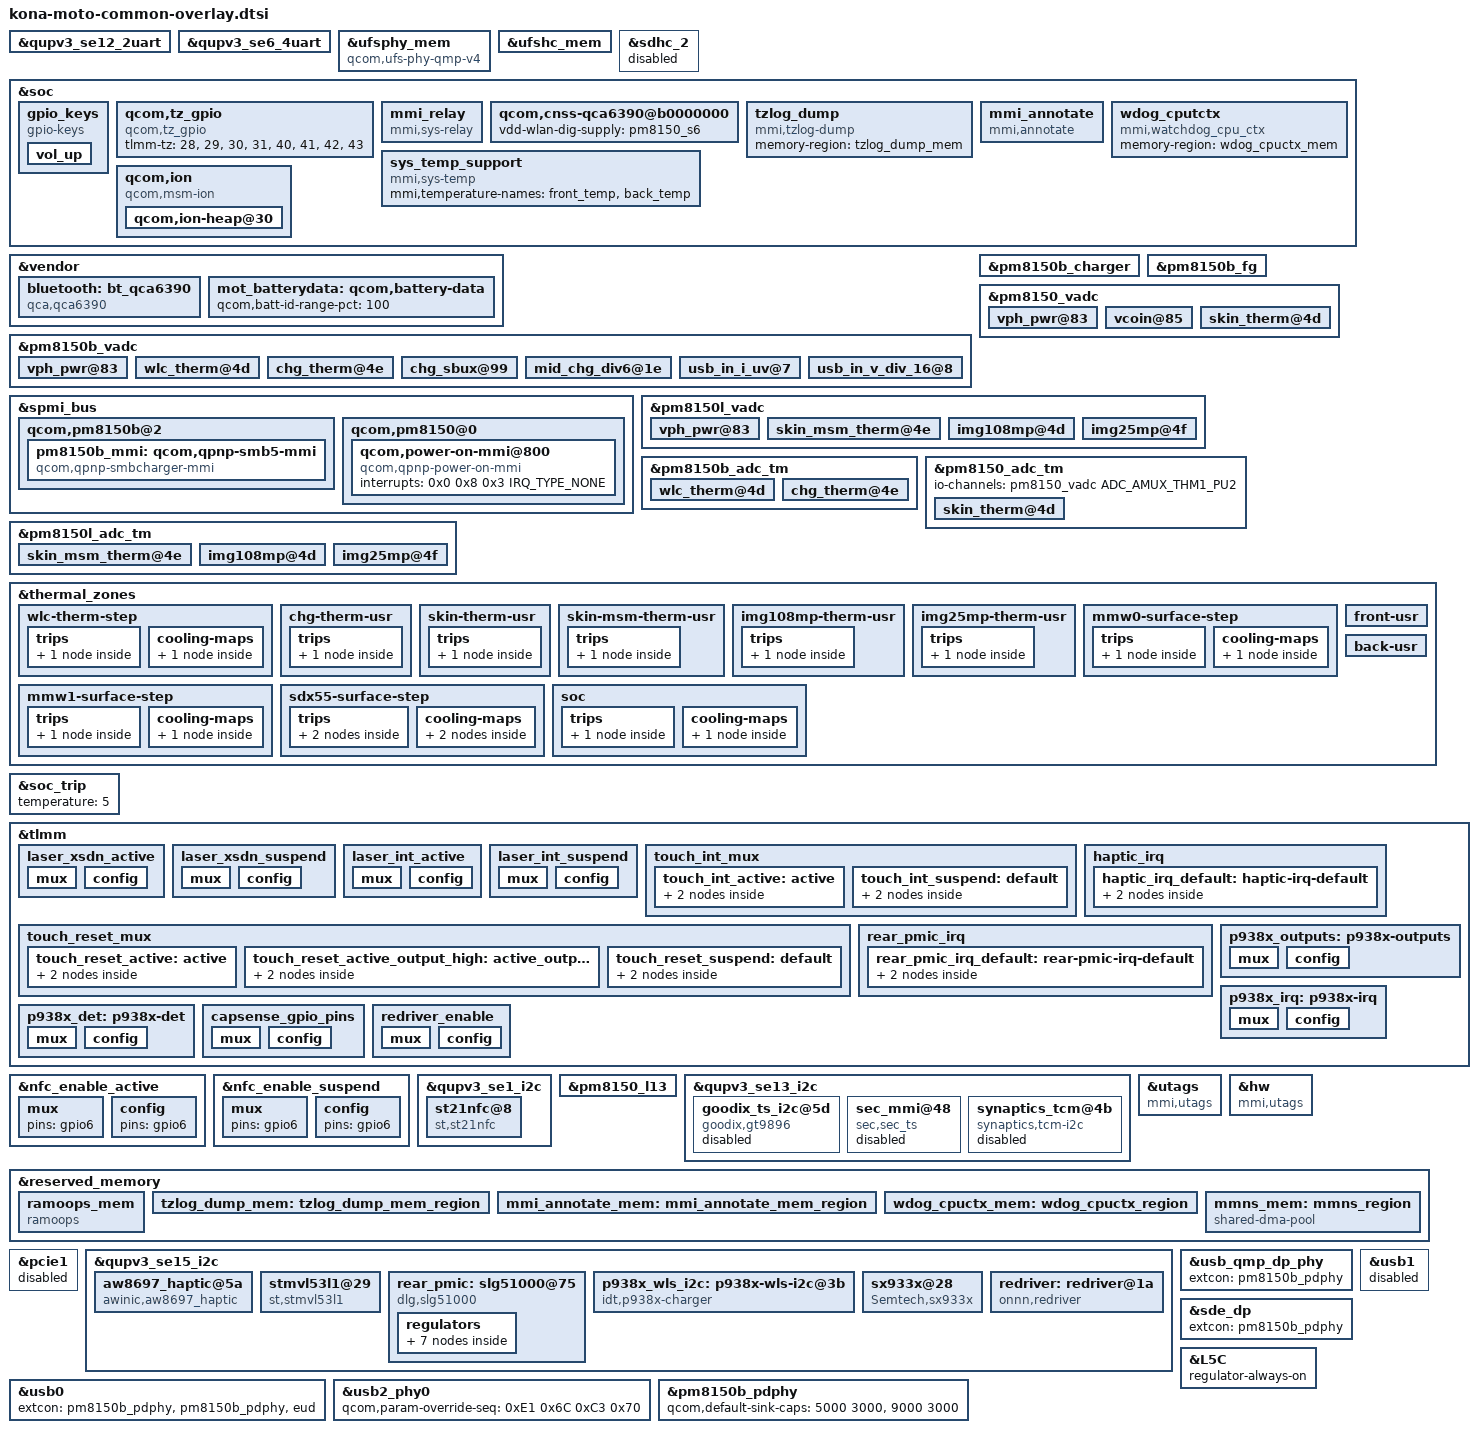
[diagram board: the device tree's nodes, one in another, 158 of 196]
#include <dt-bindings/gpio/gpio.h>
#include <dt-bindings/input/input.h>
#include "carrier-channel-ids.dtsi"

#include "camera/kona-camera-sensor-mot-burton.dtsi"
#include "kona-pmic-overlay.dtsi"
#include "kona-mot-burton-display.dtsi"
#include "kona-thermal-overlay.dtsi"
#include "kona-moto-audio-overlay.dtsi"
#include "kona-mot-burton-fps.dtsi"
&qupv3_se12_2uart {
	status = "ok";
};

&qupv3_se6_4uart {
	status = "ok";
};

&ufsphy_mem {
	compatible = "qcom,ufs-phy-qmp-v4";

	vdda-phy-supply = <&pm8150_l5>;
	vdda-phy-always-on;
	vdda-pll-supply = <&pm8150_l9>;
	vdda-phy-max-microamp = <89900>;
	vdda-pll-max-microamp = <18800>;

	status = "ok";
};

&ufshc_mem {
	vdd-hba-supply = <&ufs_phy_gdsc>;
	vdd-hba-fixed-regulator;
	vcc-supply = <&pm8150_l17>;
	vcc-voltage-level = <2504000 2950000>;
	vcc-low-voltage-sup;
	vccq-supply = <&pm8150_l6>;
	vccq2-supply = <&pm8150_s4>;
	vcc-max-microamp = <800000>;
	vccq-max-microamp = <800000>;
	vccq2-max-microamp = <800000>;

	qcom,vddp-ref-clk-supply = <&pm8150_l6>;
	qcom,vddp-ref-clk-max-microamp = <100>;
	qcom,vccq-parent-supply = <&pm8150a_s8>;
	qcom,vccq-parent-max-microamp = <210000>;

	status = "ok";
};

&sdhc_2 {
	status = "disabled";
};

&soc {
	gpio_keys {
		compatible = "gpio-keys";
		label = "gpio-keys";

		pinctrl-names = "default";
		pinctrl-0 = <&key_vol_up_default>;

		vol_up {
			label = "volume_up";
			gpios = <&pm8150_gpios 6 GPIO_ACTIVE_LOW>;
			linux,input-type = <1>;
			linux,code = <KEY_VOLUMEUP>;
			gpio-key,wakeup;
			debounce-interval = <15>;
			linux,can-disable;
		};
	};

	qcom,tz_gpio {
		compatible = "qcom,tz_gpio";
		tlmm-tz = <28>,
			<29>,
			<30>,
			<31>,
			<40>,
			<41>,
			<42>,
			<43>;
	};

	mmi_relay {
		compatible = "mmi,sys-relay";
	};
};

&vendor {
	bluetooth: bt_qca6390 {
		compatible = "qca,qca6390";
		pinctrl-names = "default";
		pinctrl-0 = <&bt_en_sleep>;
		qca,bt-reset-gpio = <&tlmm 21 0>; /* BT_EN */
		qca,bt-vdd-aon-supply = <&pm8150_s6>;
		qca,bt-vdd-dig-supply = <&pm8150_s6>;
		qca,bt-vdd-rfa1-supply = <&pm8150_s5>;
		qca,bt-vdd-rfa2-supply = <&pm8150a_s8>;

		qca,bt-vdd-aon-voltage-level = <950000 950000>;
		qca,bt-vdd-dig-voltage-level = <950000 952000>;
		qca,bt-vdd-rfa1-voltage-level = <1900000 1900000>;
		qca,bt-vdd-rfa2-voltage-level = <1350000 1350000>;

	};

	mot_batterydata: qcom,battery-data {
		qcom,batt-id-range-pct = <100>;
		#include "fg-gen4-batterydata-LW50_5000mAh.dtsi"
	};
};

&soc {
	qcom,cnss-qca6390@b0000000 {
		vdd-wlan-dig-supply = <&pm8150_s6>;
	};
};

&pm8150b_vadc {
	#address-cells = <1>;
	#size-cells = <0>;

	vph_pwr@83 {
		reg = <ADC_VPH_PWR>;
		label = "vph_pwr";
		qcom,pre-scaling = <1 3>;
	};

	wlc_therm@4d {
		reg = <ADC_AMUX_THM1_PU2>;
		label = "wlc_therm";
		qcom,ratiometric;
		qcom,hw-settle-time = <200>;
		qcom,pre-scaling = <1 1>;
	};

	chg_therm@4e {
		reg = <ADC_AMUX_THM2_PU2>;
		label = "chg_therm";
		qcom,ratiometric;
		qcom,hw-settle-time = <200>;
		qcom,pre-scaling = <1 1>;
	};

	chg_sbux@99 {
		reg = <ADC_SBUx>;
		label = "chg_sbux";
		qcom,pre-scaling = <1 3>;
	};

	mid_chg_div6@1e {
		reg = <ADC_MID_CHG_DIV6>;
		label = "chg_mid";
		qcom,pre-scaling = <1 6>;
	};

	usb_in_i_uv@7 {
		reg = <ADC_USB_IN_I>;
		label = "usb_in_i_uv";
		qcom,pre-scaling = <1 1>;
	};

	usb_in_v_div_16@8 {
		reg = <ADC_USB_IN_V_16>;
		label = "usb_in_v_div_16";
		qcom,pre-scaling = <1 16>;
	};
};

&pm8150b_charger {
	status = "ok";
	qcom,sec-charger-config = <0>;
	qcom,auto-recharge-soc = <98>;
	io-channels = <&pm8150b_vadc ADC_MID_CHG_DIV6>,
		      <&pm8150b_vadc ADC_USB_IN_I>,
		      <&pm8150b_vadc ADC_SBUx>,
		      <&pm8150b_vadc ADC_VPH_PWR>,
		      <&pm8150b_vadc ADC_CHG_TEMP>;
	io-channel-names = "mid_voltage",
			   "usb_in_current",
			   "sbux_res",
			   "vph_voltage",
			   "chg_temp";
	qcom,battery-data = <&mot_batterydata>;
	qcom,fcc-max-ua = <3600000>;
	qcom,fv-max-uv = <4450000>;
	qcom,usb-icl-ua = <3000000>;
	qcom,wd-bark-time-secs = <16>;
	qcom,suspend-input-on-debug-batt;
	qcom,usbpd-phandle = <&pm8150b_pdphy>;
	qcom,wls-current-max-ua = <1300000>;
	qcom,typec-legacy-rp-icl;
	qcom,lpd-disable;
	qcom,disable-suspend-on-collapse;
};

&spmi_bus {
	qcom,pm8150b@2 {
		pm8150b_mmi: qcom,qpnp-smb5-mmi {
			compatible = "qcom,qpnp-smbcharger-mmi";
			qcom,pmic-revid = <&pm8150b_revid>;
			vbus-supply = <&smb5_vbus>;
			status = "ok";
			qcom,enable-charging-limit;
			qcom,upper-limit-capacity = <75>;
			qcom,lower-limit-capacity = <60>;
			qcom,mmi-temp-zones =
						<0 4200 1000 0>,
						<10 4200 2500 800>,
						<15 0 2500 2500>,
						<45 4450 3600 3600>,
						<60 4200 2500 0>;
			qcom,iterm-ma = <121>;
			qcom,vfloat-comp-uv = <20000>;
		};
	};

	qcom,pm8150@0 {
		qcom,power-on-mmi@800 {
			compatible = "qcom,qpnp-power-on-mmi";
			interrupts = <0x0 0x8 0x3 IRQ_TYPE_NONE>;
			interrupt-names = "kpdpwr-bark";
		};
	};
};

&pm8150b_fg {
	status = "ok";
	qcom,battery-data = <&mot_batterydata>;
	qcom,hold-soc-while-full;
	qcom,linearize-soc;
	qcom,cl-wt-enable;
	qcom,fg-force-load-profile;
	/* ESR fast calibration */
	qcom,fg-esr-timer-chg-fast = <0 7>;
	qcom,fg-esr-timer-dischg-fast = <0 7>;
	qcom,fg-esr-timer-chg-slow = <0 96>;
	qcom,fg-esr-timer-dischg-slow = <0 96>;
	qcom,fg-esr-cal-soc-thresh = <26 230>;
	qcom,fg-esr-cal-temp-thresh = <10 40>;
	qcom,fg-cutoff-voltage = <3000>;
	qcom,fg-empty-voltage = <2750>;
	qcom,fg-sys-min-voltage = <2750>;
};

&pm8150_vadc {
	#address-cells = <1>;
	#size-cells = <0>;

	vph_pwr@83 {
		reg = <ADC_VPH_PWR>;
		label = "vph_pwr";
		qcom,pre-scaling = <1 3>;
	};

	vcoin@85 {
		reg = <ADC_VCOIN>;
		label = "vcoin";
		qcom,pre-scaling = <1 3>;
	};

	skin_therm@4d {
		reg = <ADC_AMUX_THM1_PU2>;
		label = "skin_therm";
		qcom,ratiometric;
		qcom,hw-settle-time = <200>;
		qcom,pre-scaling = <1 1>;
	};
};

&pm8150l_vadc {
	#address-cells = <1>;
	#size-cells = <0>;

	vph_pwr@83 {
		reg = <ADC_VPH_PWR>;
		label = "vph_pwr";
		qcom,pre-scaling = <1 3>;
	};

	skin_msm_therm@4e {
		reg = <ADC_AMUX_THM2_PU2>;
		label = "skin_msm_therm";
		qcom,ratiometric;
		qcom,hw-settle-time = <200>;
		qcom,pre-scaling = <1 1>;
	};

	img108mp@4d {
		reg = <ADC_AMUX_THM1_PU2>;
		label = "img108mp_therm";
		qcom,ratiometric;
		qcom,hw-settle-time = <200>;
		qcom,pre-scaling = <1 1>;
	};

	img25mp@4f {
		reg = <ADC_AMUX_THM3_PU2>;
		label = "img25mp_therm";
		qcom,ratiometric;
		qcom,hw-settle-time = <200>;
		qcom,pre-scaling = <1 1>;
	};
};

&pm8150b_adc_tm {
	#address-cells = <1>;
	#size-cells = <0>;

	io-channels = <&pm8150b_vadc ADC_AMUX_THM1_PU2>,
        <&pm8150b_vadc ADC_AMUX_THM2_PU2>;

	wlc_therm@4d {
		reg = <ADC_AMUX_THM1_PU2>;
		qcom,ratiometric;
		qcom,hw-settle-time = <200>;
	};

	chg_therm@4e {
		reg = <ADC_AMUX_THM2_PU2>;
		qcom,ratiometric;
		qcom,hw-settle-time = <200>;
	};
};

&pm8150_adc_tm {
	#address-cells = <1>;
	#size-cells = <0>;

	io-channels = <&pm8150_vadc ADC_AMUX_THM1_PU2>;

	skin_therm@4d {
		reg = <ADC_AMUX_THM1_PU2>;
		qcom,ratiometric;
		qcom,hw-settle-time = <200>;
	};
};

&pm8150l_adc_tm {
	#address-cells = <1>;
	#size-cells = <0>;

	io-channels = <&pm8150l_vadc ADC_AMUX_THM2_PU2>,
			<&pm8150l_vadc ADC_AMUX_THM1_PU2>,
			<&pm8150l_vadc ADC_AMUX_THM3_PU2>;

	skin_msm_therm@4e {
		reg = <ADC_AMUX_THM2_PU2>;
		qcom,ratiometric;
		qcom,hw-settle-time = <200>;
	};

	img108mp@4d {
		reg = <ADC_AMUX_THM1_PU2>;
		qcom,ratiometric;
		qcom,hw-settle-time = <200>;
	};

	img25mp@4f {
		reg = <ADC_AMUX_THM3_PU2>;
		qcom,ratiometric;
		qcom,hw-settle-time = <200>;
	};
};

&thermal_zones {
	wlc-therm-step {
		polling-delay-passive = <0>;
		polling-delay = <0>;
		thermal-governor = "step_wise";
		thermal-sensors = <&pm8150b_adc_tm ADC_AMUX_THM1_PU2>;
		trips {
			wlc_trip0: wlc-trip0 {
				temperature = <50000>;
				hysteresis = <3000>;
				type = "passive";
			};
		};
		cooling-maps {
			wlc-trip-lvl0 {
				trip = <&wlc_trip0>;
				cooling-device = <&p938x_wls_i2c 1 1>;
			};
		};
	};

	chg-therm-usr {
		polling-delay-passive = <0>;
		polling-delay = <0>;
		thermal-governor = "user_space";
		thermal-sensors = <&pm8150b_adc_tm ADC_AMUX_THM2_PU2>;
		trips {
			active-config0 {
				temperature = <125000>;
				hysteresis = <1000>;
				type = "passive";
			};
		};
	};

	skin-therm-usr {
		polling-delay-passive = <0>;
		polling-delay = <0>;
		thermal-governor = "user_space";
		thermal-sensors = <&pm8150_adc_tm ADC_AMUX_THM1_PU2>;
		trips {
			active-config0 {
				temperature = <125000>;
				hysteresis = <1000>;
				type = "passive";
			};
		};
	};

	skin-msm-therm-usr {
		polling-delay-passive = <0>;
		polling-delay = <0>;
		thermal-governor = "user_space";
		thermal-sensors = <&pm8150l_adc_tm ADC_AMUX_THM2_PU2>;
		trips {
			active-config0 {
				temperature = <125000>;
				hysteresis = <1000>;
				type = "passive";
			};
		};
	};

	img108mp-therm-usr {
		polling-delay-passive = <0>;
		polling-delay = <0>;
		thermal-governor = "user_space";
		thermal-sensors = <&pm8150l_adc_tm ADC_AMUX_THM1_PU2>;
		trips {
			active-config0 {
				temperature = <125000>;
				hysteresis = <1000>;
				type = "passive";
			};
		};
	};

	img25mp-therm-usr {
		polling-delay-passive = <0>;
		polling-delay = <0>;
		thermal-governor = "user_space";
		thermal-sensors = <&pm8150l_adc_tm ADC_AMUX_THM3_PU2>;
		trips {
			active-config0 {
				temperature = <125000>;
				hysteresis = <1000>;
				type = "passive";
			};
		};
	};

	mmw0-surface-step {
		polling-delay-passive = <2000>;
		polling-delay = <2000>;
		thermal-governor = "step_wise";
		trips {
			modem_skin0_trip0: modem-skin0-trip0 {
				temperature = <48000>;
				hysteresis = <5000>;
				type = "passive";
			};
		};
		cooling-maps {
			skin0_modem_lvl2 {
				trip = <&modem_skin0_trip0>;
				cooling-device = <&modem_mmw0 2 2>;
			};
		};
	};

	mmw1-surface-step {
		polling-delay-passive = <2000>;
		polling-delay = <2000>;
		thermal-governor = "step_wise";
		trips {
			modem_skin1_trip0: modem-skin1-trip0 {
				temperature = <48000>;
				hysteresis = <5000>;
				type = "passive";
			};
		};
		cooling-maps {
			skin1_modem_lvl2 {
				trip = <&modem_skin1_trip0>;
				cooling-device = <&modem_mmw1 2 2>;
			};
		};
	};

	sdx55-surface-step {
		polling-delay-passive = <2000>;
		polling-delay = <2000>;
		thermal-governor = "step_wise";
		trips {
			modem_skin_trip1: modem-skin-trip1 {
				temperature = <44000>;
				hysteresis = <2000>;
				type = "passive";
			};
			modem_skin_trip2: modem-skin-trip2 {
				temperature = <47000>;
				hysteresis = <5000>;
				type = "passive";
			};
		};
		cooling-maps {
			/* CQI=0 */
			modem_skin_l1 {
				trip = <&modem_skin_trip1>;
				cooling-device = <&modem_skin 1 1>;
			};
			/* Disable 5G */
			modem_skin_l2 {
				trip = <&modem_skin_trip2>;
				cooling-device = <&modem_skin 2 2>;
			};
		};
	};

	front-usr {
		polling-delay-passive = <2000>;
		polling-delay = <2000>;
		thermal-governor = "user_space";
	};

	back-usr {
		polling-delay-passive = <2000>;
		polling-delay = <2000>;
		thermal-governor = "user_space";
	};
};

&thermal_zones {
	soc {
		trips {
			soc_trip2:soc-trip2 {
				temperature = <15>;
				hysteresis = <0>;
				type = "passive";
			};
		};
		cooling-maps {
			soc_modem {
				trip = <&soc_trip2>;
				cooling-device = <&modem_mmw0 3 3>;
			};
		};
	};
};

&soc_trip {
	temperature = <5>;
};

&tlmm{
	laser_xsdn_active: laser_xsdn_active {
		mux {
			pins = "gpio10";
			function = "gpio";
		};

		config {
			pins = "gpio10";
			drive-strength = <2>;
			bias-disable;
		};
	};

	laser_xsdn_suspend: laser_xsdn_suspend {
		mux {
			pins = "gpio10";
			function = "gpio";
		};

		config {
			pins = "gpio10";
			drive-strength = <2>;
			bias-pull-down; /* PULL DOWN */
		};
	};

	laser_int_active: laser_int_active {
		mux {
			pins = "gpio11";
			function = "gpio";
		};

		config {
			pins = "gpio11";
			drive-strength = <2>;
			bias-pull-up; /* PULL UP */
		};
	};

	laser_int_suspend: laser_int_suspend {
		mux {
			pins = "gpio11";
			function = "gpio";
		};

		config {
			pins = "gpio11";
			drive-strength = <2>;
			bias-pull-down; /* PULL DOWN */
		};
	};

	touch_int_mux {
		touch_int_active: active {
			mux {
				pins = "gpio39";
				function = "gpio";
			};
			config {
				pins = "gpio39";
				drive-strength = <2>;
				bias-pull-up;
			};
		};

		touch_int_suspend: default {
			mux {
				pins = "gpio39";
				function = "gpio";
			};
			config {
				pins = "gpio39";
				drive-strength = <2>;
				bias-disable;
			};
		};
	};

	touch_reset_mux {
		touch_reset_active: active {
			mux {
				pins = "gpio38";
				function = "gpio";
			};
			config {
				pins = "gpio38";
				drive-strength = <2>;
				bias-disable;
			};
		};

		touch_reset_active_output_high: active_output_high {
			mux {
				pins = "gpio38";
				function = "gpio";
			};
			config {
				pins = "gpio38";
				drive-strength = <2>;
				bias-disable;
				output-high;
			};
		};

		touch_reset_suspend: default {
			mux {
				pins = "gpio38";
				function = "gpio";
			};
			config {
				pins = "gpio38";
				drive-strength = <2>;
				bias-pull-down;
				output-low;
			};
		};
	};
};

/* ST54JNFC */
&nfc_enable_active {
	mux {
		pins = "gpio6";
	};
	config {
		pins = "gpio6";
	};
};

&nfc_enable_suspend {
	mux {
		pins = "gpio6";
	};
	config {
		pins = "gpio6";
	};
};

&qupv3_se1_i2c {
	status = "ok";

	st21nfc@8 {
		compatible = "st,st21nfc";
		status = "ok";
		reg = <0x08>;
		st,irq_gpio = <&tlmm 111 0x00>;
		st,reset_gpio = <&tlmm 6 0x00>;
		st,clkreq_gpio = <&tlmm 7 0x00>;
		interrupt-parent = <&tlmm>;
		interrupts = <111 0>;
		interrupt-names = "nfc_irq";
		pinctrl-names = "nfc_active", "nfc_suspend";
		pinctrl-0 = <&nfc_int_active &nfc_enable_active &nfc_clk_req_active>;
		pinctrl-1 = <&nfc_int_suspend &nfc_enable_suspend &nfc_clk_req_suspend>;
	};
};

&pm8150_l13 {
	regulator-min-microvolt = <3304000>;
	regulator-max-microvolt = <3304000>;
	qcom,init-voltage = <3304000>;
};

&qupv3_se13_i2c {
	status = "okay";

	goodix_ts_i2c@5d {
		status = "/chosen","mmi,panel_name","contains","boe_gdx","csot_gdx";
		compatible = "goodix,gt9896";
		reg = <0x5d>;
		interrupt-parent = <&tlmm>;
		interrupts = <39 0>;
		pinctrl-names = "pmx_ts_active","pmx_ts_suspend";
		pinctrl-0 = <&touch_int_active &touch_reset_active>;
		pinctrl-1 = <&touch_int_suspend &touch_reset_suspend>;
		/*goodix,reg-en-gpio = <&tlmm 120 0x0>;*/
		goodix,avdd-name = "pm8150_l13";
		goodix,iovdd-name = "pm8150a_l1";
		goodix,reset-gpio = <&tlmm 38 0x0>;
		goodix,irq-gpio = <&tlmm 39 0x2002>;
		goodix,irq-flags = <0x2002>; /* 1:trigger rising, 2:trigger falling;*/
		goodix,control-dsi = <0>;
		goodix,panel-max-id = <10>;
		goodix,panel-max-x = <1080>;
		goodix,panel-max-y = <2340>;
		goodix,panel-max-w = <256>;
		goodix,panel-max-p = <4096>;
		/*goodix,power-on-delay-us = <300000>; *300ms*/
		goodix,power-off-delay-us = <5000>;
		/*goodix,swap-axis;*/
		/*goodix,x2x;*/
		/*goodix,y2y;*/
		goodix,usb_charger;
		goodix,cfg_bin_name = "goodix_cfg_group.bin";
		goodix,fw_name = "goodix-gtx8-01-14-burton.bin";
	};

	sec_mmi@48 {
		status = "/chosen","mmi,panel_name","contains","boe_lsi","csot_lsi";
		compatible = "sec,sec_ts";
		reg = <0x48>;
		sec,rst_gpio = <&tlmm 38 0>;
		sec,irq_gpio = <&tlmm 39 0>;
		sec,irq_type = <0x2008>; /*IRQF_TRIGGER_LOW | IRQF_ONESHOT*/
		sec,max_coords = <1080 2340>;
		sec,size_to_pixel_multiple_factor = <1948>;
		sec,regulator_dvdd = "pm8150a_l1";
		sec,regulator_avdd = "pm8150_l13";
		sec,suppression-control;
		sec,pill-region-control;
		sec,hold-distance-control;
		sec,gs-distance-control;
		sec,hold-grip-control;
		pinctrl-names = "on_state", "off_state";
		pinctrl-0 = <&touch_reset_active &touch_int_active>;
		pinctrl-1 = <&touch_reset_suspend &touch_int_suspend>;
		/* touchscreen_mmi class entries */
		mmi,refresh-rate-update;
		mmi,enable-gestures;
		mmi,usb-charger-detection;
		mmi,power-off-suspend;
	};

	synaptics_tcm@4b {
		status = "/chosen","mmi,panel_name","contains","tianma_syna";
		compatible = "synaptics,tcm-i2c";
		reg = <0x4b>;
		interrupt-parent = <&tlmm>;
		interrupts = <39 0x2008>;
		synaptics,irq-gpio = <&tlmm 39 0x2008>; /*IRQF_TRIGGER_LOW | IRQF_ONESHOT*/
		synaptics,irq-on-state = <0>;
		synaptics,reset-gpio = <&tlmm 38 0x0000>;
		synaptics,reset-on-state = <0>;
		synaptics,reset-active-ms = <0>;
		synaptics,reset-delay-ms = <200>;
		synaptics,power-delay-ms = <200>;
		synaptics,ubl-i2c-addr = <0x4b>;
		synaptics,pwr-reg-name = "pm8150_l13";
		synaptics,bus-reg-name = "pm8150a_l1";
		pinctrl-names = "ts_mmi_on_state", "ts_mmi_off_state";
		pinctrl-0 = <&touch_reset_active_output_high &touch_int_active>;
		pinctrl-1 = <&touch_reset_suspend &touch_int_suspend>;
		synaptics,size_to_pixel_multiple_factor = <1948>;
		/* touchscreen_mmi class entries */
		mmi,max_coords = <1080 2340>;
		mmi,poison-slot-control;
		mmi,enable-gestures;
		mmi,usb-charger-detection;
		mmi,power-off-suspend;
		mmi,suppression-control;
		mmi,gs-distance-control;
		mmi,pill-region-control;
		mmi,hold-distance-control;
		mmi,fps_detection;
	};
};

&utags {
	compatible = "mmi,utags";
	mmi,main-utags = "/dev/block/bootdevice/by-name/utags";
	mmi,backup-utags = "/dev/block/bootdevice/by-name/utagsBackup";
};

&hw {
	compatible = "mmi,utags";
	mmi,dir-name = "hw";
	mmi,main-utags = "/dev/block/bootdevice/by-name/hw";
};

&reserved_memory{
	ramoops_mem {
		compatible = "ramoops";
		no-map;
		reg = <0x0 0xaf000000 0x0 0xc0000>;
		console-size = <0x40000>;
		pmsg-size = <0x40000>;
		record-size = <0x3f800>;
	};

	tzlog_dump_mem: tzlog_dump_mem_region {
		no-map;
		reg = <0x0 0xaefd0000 0x0 0x30000>;
	};

	mmi_annotate_mem: mmi_annotate_mem_region {
		no-map;
		reg = <0x0 0xaefcf800 0x0 0x800>;
	};

	wdog_cpuctx_mem: wdog_cpuctx_region {
		no-map;
		reg = <0x0 0xaef9d800 0x0 (0x6400 * 8)>;
	};

	mmns_mem: mmns_region {
		compatible = "shared-dma-pool";
		reusable;
		alignment = <0x0 0x400000>;
		size = <0 0x2D000000>;
	};
};

&soc {
	tzlog_dump {
		compatible = "mmi,tzlog-dump";
		memory-region = <&tzlog_dump_mem>;
	};

	mmi_annotate {
		compatible = "mmi,annotate";
		memory-region = <&mmi_annotate_mem>;
		mem-size = <0x20000>;
	};

	wdog_cputctx {
		compatible = "mmi,watchdog_cpu_ctx";
		memory-region = <&wdog_cpuctx_mem>;
	};

	sys_temp_support {
		compatible = "mmi,sys-temp";
		mmi,temperature-names = "front_temp",
					"back_temp";
		status = "ok";
	};

	qcom,ion {
		compatible = "qcom,msm-ion";
		qcom,ion-heap@30 { /* MMNS HEAP */
			reg = <30>;
			memory-region = <&mmns_mem>;
			qcom,ion-heap-type = "DMA_RESERVED";
		};
	};
};

&tlmm{
	haptic_irq {
		haptic_irq_default: haptic-irq-default {
			mux {
				pins = "gpio136";
				function = "gpio";
			};
			config {
				pins = "gpio136";
				drive-strength = <2>;   /* 2 mA */
				bias-pull-up;
			};
		};
	};

	rear_pmic_irq {
		rear_pmic_irq_default: rear-pmic-irq-default {
			mux {
				pins = "gpio129";
				function = "gpio";
			};
			config {
				pins = "gpio129";
				drive-strength = <2>;   /* 2 mA */
				bias-pull-up;
			};
		};
	};

	p938x_outputs: p938x-outputs {
		mux {
			pins = "gpio107", "gpio82", "gpio131";
			function = "gpio";
		};

		config {
			pins = "gpio107", "gpio82", "gpio131";
			drive-strength = <2>;
			bias-pull-up;
			output-low;
		};
	};

	p938x_irq: p938x-irq {
		mux {
			pins = "gpio108";
			function = "gpio";
		};

		config {
			pins = "gpio108";
			drive-strength = <2>;
			bias-pull-up;
			input-enable;
		};
	};

	p938x_det: p938x-det {
		mux {
			pins = "gpio83";
			function = "gpio";
		};

		config {
			pins = "gpio83";
			drive-strength = <2>;
			bias-pull-down;
			input-enable;
		};
	};

	capsense_gpio_pins: capsense_gpio_pins {
		mux {
			pins = "gpio64";
			function = "gpio";
		};
		config {
			pins = "gpio64";
			drive-strength = <2>;
			bias-disable;
		};
	};
	redriver_enable: redriver_enable {
		mux {
			pins = "gpio61";
			function = "gpio";
		};

		config {
			pins = "gpio61";
			drive-strength = <2>;
			bias-pull-up;
			output-high;
		};
	};
};

/* Need gpio 82 & 83 for WCHG */
&pcie1 {
	status = "disabled";
};

&qupv3_se15_i2c {
	status = "okay";

	aw8697_haptic@5a {
		status = "okay";
		compatible = "awinic,aw8697_haptic";
		reg = <0x5A>;
		reset-gpio = <&tlmm 135 0>;
		irq-gpio = <&tlmm 136 0>;
		vib_mode = <1>;   /*mode:   RAM mode->0; CONT mode -> 1*/
		vib_f0_pre = <1700>;
		vib_f0_cali_percen = <7>;
		vib_cont_drv_lev = <78>;
		vib_cont_drv_lvl_ov = <98>;
		vib_cont_td = <0x009a>;
		vib_cont_zc_thr = <0x0ff1>;
		vib_cont_num_brk = <3>;
		vib_f0_coeff = <260>; /*Don't modify it    2.604167*/
		vib_f0_trace_parameter = <0x05 0x03 0x02 0x0f>;
		vib_bemf_config = <0x10 0x08 0x03 0xf8>;
		vib_sw_brake = <0x2c>;
		vib_tset = <0x12>;
		vib_r_spare = <0x68>;
                vib_bstdbg = <0x30 0xeb 0xd4 0 0 0>;
		pinctrl-names = "default";
		pinctrl-0 = <&haptic_irq_default>;
	};

	stmvl53l1@29 {
		/* Enable once the matching driver is ported completely */
		status = "ok";
		compatible = "st,stmvl53l1";
		reg = <0x29>;
		vdd-vl53l1-supply = <&pm8150a_l7>;
		gpios = <&tlmm 10 0>, <&tlmm 11 0>;
		qcom,gpio-reset = <0>;
		qcom,gpio-req-tbl-num = <0 1>;
		qcom,gpio-req-tbl-flags = <0 1>;
		qcom,gpio-req-tbl-label ="TOF_XSHUTDOWN","TOF_INT";
		pinctrl-names = "laser_default", "laser_suspend";
		pinctrl-0 = <&laser_xsdn_active &laser_int_active>;
		pinctrl-1 = <&laser_xsdn_suspend &laser_int_suspend>;
		st,sensorthreshold = <60 65>;
		st,xtalkval = <0x3E8 0xFACD 0x0>;
	};

	rear_pmic: slg51000@75 {
		compatible = "dlg,slg51000";
		reg = <0x75>;

		interrupt-parent = <&tlmm>;
		interrupts = <129 IRQ_TYPE_LEVEL_HIGH>;
		dlg,cs-gpios = <&pm8150l_gpios 5 0>;

		pinctrl-names = "default";
		pinctrl-0 = <&rear_pmic_irq_default>;
		use-default-voltage;

		regulators {
			cam_main_avdd_2p8: ldo1 {
				regulator-name = "ldo1";
				regulator-min-microvolt = <2400000>;
				regulator-max-microvolt = <3300000>;
			};

			cam_wfov_tele_avdd_2p8: ldo2 {
				regulator-name = "ldo2";
				regulator-min-microvolt = <2400000>;
				regulator-max-microvolt = <3300000>;
			};

			cam_main_afois_vdd_3p5: ldo3 {
				regulator-name = "ldo3";
				regulator-min-microvolt = <1200000>;
				regulator-max-microvolt = <3750000>;
			};

			cam_wfov_tele_afvdd_2p8: ldo4 {
				regulator-name = "ldo4";
				regulator-min-microvolt = <1200000>;
				regulator-max-microvolt = <3750000>;
			};

			cam_main_dvdd_1p05: ldo5 {
				regulator-name = "ldo5";
				regulator-min-microvolt = <500000>;
				regulator-max-microvolt = <1200000>;
			};

			cam_wfov_dvdd_1p2: ldo6 {
				regulator-name = "ldo6";
				regulator-min-microvolt = <500000>;
				regulator-max-microvolt = <1200000>;
			};

			cam_tele_dvdd_1p2: ldo7 {
				regulator-name = "ldo7";
				regulator-min-microvolt = <1200000>;
				regulator-max-microvolt = <3750000>;
			};
		};
	};

	p938x_wls_i2c: p938x-wls-i2c@3b {
		compatible = "idt,p938x-charger";
		reg = <0x3b>;
		interrupt-parent = <&tlmm>;
		interrupts = <108 0x1>;
		gpios = <&tlmm 108 GPIO_ACTIVE_LOW>, /* WCHG_INT_N */
				<&tlmm 107 GPIO_ACTIVE_LOW>, /* WCHG_EN_N */
				<&tlmm 83 GPIO_ACTIVE_HIGH>,  /* WCHG_DET */
				<&tlmm 82 GPIO_ACTIVE_HIGH>,  /* WCHG_SLEEP */
				<&tlmm 131 GPIO_ACTIVE_HIGH>; /* WCHG_BOOST_EN */
		gpio-names = "idt_p938x_irq",
					 "idt_p938x_enable",
					 "idt_p938x_det",
					 "idt_p938x_sleep",
					 "idt_p938x_boost";
		pinctrl-names = "default";
		pinctrl-0 = <&p938x_outputs &p938x_irq &p938x_det>;
		bpp-current = <950>;
		epp-current-table =
			<0 450>, <8000 750>, <10000 950>, <15000 1350>;
		bpp-voltage = <5000>;
		epp-voltage = <10000>;
		vdd-i2c-supply = <&dummy_vreg>;
		/* Setting 0x0320, 0x0258, 0x0DAC. They are little endian,
		 * so swap them in the byte array */
		fod-array-tx-val = [20 03 58 02 AC 0D];
		#cooling-cells = <2>;
	};

	sx933x@28 {
		compatible = "Semtech,sx933x";
		reg = <0x28>;
		interrupt-parent = <&tlmm>;
		interrupts = <64 0>;
		Semtech,nirq-gpio = <&tlmm 64 0x00>;
		pinctrl-names = "default";
		pinctrl-0 = <&capsense_gpio_pins>;
		cap_vdd-supply = <&pm8150a_l10>;
		Semtech,reg-num = <45>;
		Semtech,button-flag = <0x1F>;
		Semtech,reg-init = <0x8020 0x001F0000
			0x801c 0x00000033
			0x8024 0x11000846
			0x8028 0x3ffe8000
			0x802C 0x300014d4
			0x8030 0x3ff78000
			0x8034 0x11000646
			0x8038 0x3fbf8000
			0x803C 0x11001046
			0x8040 0x3dff8000
			0x8044 0x20000876
			0x8048 0x2fff8000
			0x8054 0x01304300 /*ph0*/
			0x8058 0x20600c00
			0x805c 0x00000000
			0x8064 0x00C30000
			0x806C 0x3E003E00
			0x8070 0x00010000
			0x8074 0x00000000 /*ph1*/
			0x8078 0x3E770B00
			0x807c 0x00000000
			0x808c 0x00000000
			0x8090 0x00000000
			0x8094 0x01204600 /*ph2*/
			0x8098 0x20600c00
			0x809c 0x00000000
			0x80A4 0x00d40000
			0x80AC 0x00690069
			0x80B0 0x00020000
			0x80B4 0x093b3200 /*ph3*/
			0x80b8 0x20600c00
			0x80bc 0x00000000
			0x80C4 0x00640000
			0x80CC 0x002e002d
			0x80D0 0x00020000
			0x80D4 0x0a104000 /*ph4*/
			0x80d8 0x20600c00
			0x80dc 0x00000000
			0x80E4 0x00ff0000
			0x80EC 0x00000000
			0x80F0 0x00000000
			0x8124 0x04000009
			0x8128 0x0400000C
			0x4004 0x00000074
			0x4054 0x00010400 >;
	};
	redriver: redriver@1a {
		compatible = "onnn,redriver";
		reg = <0x1a>;
		extcon = <&pm8150b_pdphy>, <&pm8150b_pdphy>;
		pinctrl-names = "default";
		pinctrl-0 = <&redriver_enable>;
		eq = /bits/ 8 <
				/* Parameters for USB */
				0x4 0x4 0x4 0x4
				/* Parameters for DP */
				0x6 0x4 0x4 0x6>;
		flat-gain = /bits/ 8 <
				/* Parameters for USB */
				0x3 0x1 0x1 0x3
				/* Parameters for DP */
				0x2 0x1 0x1 0x2>;
		output-comp = /bits/ 8 <
				/* Parameters for USB */
				0x3 0x3 0x3 0x3
				/* Parameters for DP */
				0x3 0x3 0x3 0x3>;
		loss-match = /bits/ 8 <
				/* Parameters for USB */
				0x1 0x3 0x3 0x1
				/* Parameters for DP */
				0x3 0x3 0x3 0x3>;
	};
};

&usb0 {
	extcon = <&pm8150b_pdphy>, <&pm8150b_pdphy>, <&eud>;
};

&usb2_phy0 {
	qcom,param-override-seq = <0xE1 0x6C
				   0xC3 0x70>;
};

&usb_qmp_dp_phy {
	extcon = <&pm8150b_pdphy>;
};

&sde_dp {
	extcon = <&pm8150b_pdphy>;
};

&usb1 {
	status = "disabled";
};

&pm8150b_pdphy{
	qcom,default-sink-caps = <5000 3000>, /* 5V @ 3A */
				 <9000 3000>; /* 9V @ 3A */
};

&L5C {
	regulator-always-on;
};
